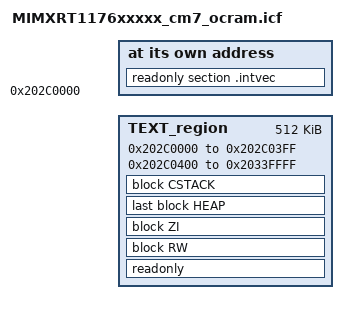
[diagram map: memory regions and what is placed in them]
/*
** ###################################################################
**     Processors:          MIMXRT1176AVM8A_cm4
**                          MIMXRT1176CVM8A_cm4
**                          MIMXRT1176DVMAA_cm4
**
**     Compiler:            IAR ANSI C/C++ Compiler for ARM
**     Reference manual:    IMXRT1170RM, Rev E, 12/2019
**     Version:             rev. 0.1, 2018-03-05
**     Build:               b200226
**
**     Abstract:
**         Linker file for the IAR ANSI C/C++ Compiler for ARM
**
**     Copyright 2016 Freescale Semiconductor, Inc.
**     Copyright 2016-2020 NXP
**     All rights reserved.
**
**     SPDX-License-Identifier: BSD-3-Clause
**
**     http:                 www.nxp.com
**     mail:                 support@nxp.com
**
** ###################################################################
*/

define symbol m_interrupts_start       = 0x202C0000;
define symbol m_interrupts_end         = 0x202C03FF;

define symbol m_text_start             = 0x202C0400;
define symbol m_text_end               = 0x2033FFFF;

/* Sizes */
if (isdefinedsymbol(__stack_size__)) {
  define symbol __size_cstack__        = __stack_size__;
} else {
  define symbol __size_cstack__        = 0x0400;
}

if (isdefinedsymbol(__heap_size__)) {
  define symbol __size_heap__          = __heap_size__;
} else {
  define symbol __size_heap__          = 0x0400;
}

define exported symbol __VECTOR_TABLE          = m_interrupts_start;
define exported symbol __VECTOR_RAM            = m_interrupts_start;
define exported symbol __RAM_VECTOR_TABLE_SIZE = 0x0;

define memory mem with size = 4G;
define region TEXT_region = mem:[from m_interrupts_start to m_interrupts_end]
                          | mem:[from m_text_start to m_text_end];

define block CSTACK    with alignment = 8, size = __size_cstack__   { };
define block HEAP      with alignment = 8, size = __size_heap__     { };
define block RW        { readwrite };
define block ZI        { zi };

initialize by copy { readwrite, section .textrw };
do not initialize  { section .noinit };

place at address mem: m_interrupts_start    { readonly section .intvec };

place in TEXT_region                        { readonly };
place in TEXT_region                        { block RW };
place in TEXT_region                        { block ZI };
place in TEXT_region                        { last block HEAP };
place in TEXT_region                        { block CSTACK };
